VERSION "All_Common"

NS_ :

BS_:

BU_: PCM UNKNOWN

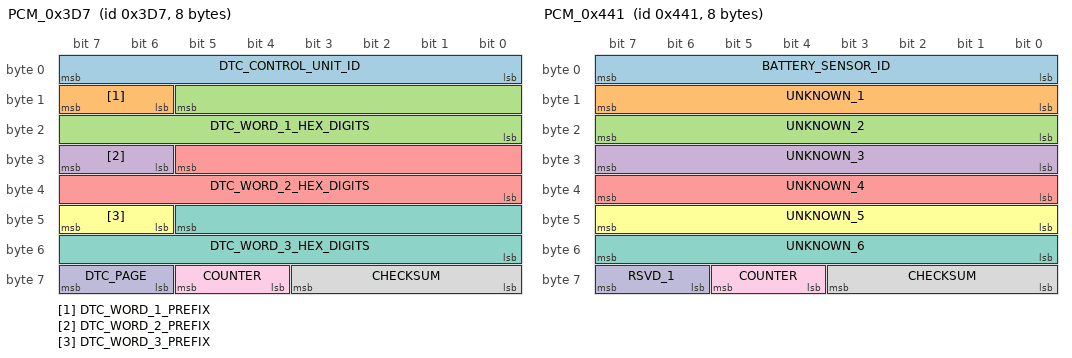
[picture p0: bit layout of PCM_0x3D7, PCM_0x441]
BO_ 983 PCM_0x3D7: 8 PCM
 SG_ DTC_CONTROL_UNIT_ID : 0|8@1+ (1,0) [0|255] ""  UNKNOWN
 SG_ DTC_WORD_1_PREFIX : 15|2@0+ (1,0) [0|3] ""  UNKNOWN
 SG_ DTC_WORD_1_HEX_DIGITS : 13|14@0+ (1,0) [0|16383] ""  UNKNOWN
 SG_ DTC_WORD_2_PREFIX : 31|2@0+ (1,0) [0|3] ""  UNKNOWN
 SG_ DTC_WORD_2_HEX_DIGITS : 29|14@0+ (1,0) [0|16383] ""  UNKNOWN
 SG_ DTC_WORD_3_PREFIX : 47|2@0+ (1,0) [0|3] ""  UNKNOWN
 SG_ DTC_WORD_3_HEX_DIGITS : 45|14@0+ (1,0) [0|16383] ""  UNKNOWN
 SG_ CHECKSUM : 56|4@1+ (1,0) [0|15] ""  UNKNOWN
 SG_ COUNTER : 60|2@1+ (1,0) [0|3] ""  UNKNOWN
 SG_ DTC_PAGE : 62|2@1+ (1,0) [0|3] ""  UNKNOWN
VAL_ 983 DTC_PAGE 0 "DTC_SLOTS_1_TO_3" 1 "DTC_SLOTS_4_TO_6" ;
VAL_ 983 DTC_CONTROL_UNIT_ID 176 "PCM" ;
VAL_ 983 DTC_WORD_1_PREFIX 0 "P" 1 "C" 2 "B" 3 "U" ;
VAL_ 983 DTC_WORD_2_PREFIX 0 "P" 1 "C" 2 "B" 3 "U" ;
VAL_ 983 DTC_WORD_3_PREFIX 0 "P" 1 "C" 2 "B" 3 "U" ;
CM_ BO_ 983 "Read digits as four hex characters. P0000 marks an empty slot.";

BO_ 1089 PCM_0x441: 8 PCM
 SG_ BATTERY_SENSOR_ID : 0|8@1+ (1,0) [0|255] ""  UNKNOWN
 SG_ UNKNOWN_1 : 8|8@1+ (1,0) [0|255] ""  UNKNOWN
 SG_ UNKNOWN_2 : 16|8@1+ (1,0) [0|255] ""  UNKNOWN
 SG_ UNKNOWN_3 : 24|8@1+ (1,0) [0|255] ""  UNKNOWN
 SG_ UNKNOWN_4 : 32|8@1+ (1,0) [0|255] ""  UNKNOWN
 SG_ UNKNOWN_5 : 40|8@1+ (1,0) [0|255] ""  UNKNOWN
 SG_ UNKNOWN_6 : 48|8@1+ (1,0) [0|255] ""  UNKNOWN
 SG_ CHECKSUM : 56|4@1+ (1,0) [0|15] ""  UNKNOWN
 SG_ COUNTER : 60|2@1+ (1,0) [0|3] ""  UNKNOWN
 SG_ RSVD_1 : 62|2@1+ (1,0) [0|3] ""  UNKNOWN
CM_ SG_ 1089 BATTERY_SENSOR_ID "PCM-supplied configuration ID";

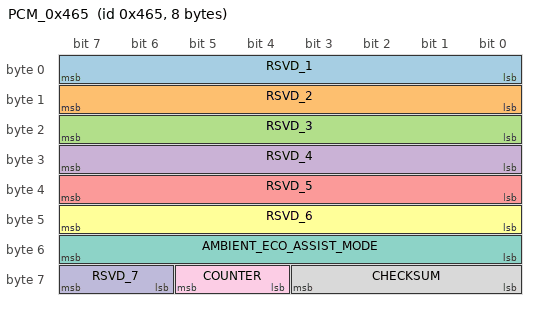
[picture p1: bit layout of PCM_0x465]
BO_ 1125 PCM_0x465: 8 PCM
 SG_ RSVD_1 : 0|8@1+ (1,0) [0|255] ""  UNKNOWN
 SG_ RSVD_2 : 8|8@1+ (1,0) [0|255] ""  UNKNOWN
 SG_ RSVD_3 : 16|8@1+ (1,0) [0|255] ""  UNKNOWN
 SG_ RSVD_4 : 24|8@1+ (1,0) [0|255] ""  UNKNOWN
 SG_ RSVD_5 : 32|8@1+ (1,0) [0|255] ""  UNKNOWN
 SG_ RSVD_6 : 40|8@1+ (1,0) [0|255] ""  UNKNOWN
 SG_ AMBIENT_ECO_ASSIST_MODE : 48|8@1+ (1,0) [0|255] ""  UNKNOWN
 SG_ CHECKSUM : 56|4@1+ (1,0) [0|15] ""  UNKNOWN
 SG_ COUNTER : 60|2@1+ (1,0) [0|3] ""  UNKNOWN
 SG_ RSVD_7 : 62|2@1+ (1,0) [0|3] ""  UNKNOWN
VAL_ 1125 AMBIENT_ECO_ASSIST_MODE 0 "OFF" 1 "WHITE" 2 "LIGHT_GREEN" 3 "GREEN" ;
